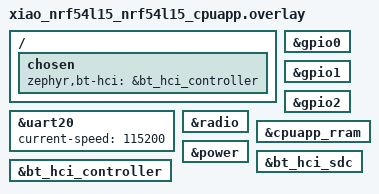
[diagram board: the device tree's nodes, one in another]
// XIAO nRF54L15 BLE Button Sample Device Tree Overlay
// Uses existing led0 and sw0 aliases from board definition

/ {
	// Use existing aliases - no need to redefine
};

// Enable GPIO controllers
&gpio0 {
	status = "okay";
};

&gpio1 {
	status = "okay";
};

&gpio2 {
	status = "okay";
};

// Configure UART for console output
&uart20 {
	status = "okay";
	current-speed = <115200>;
};

// Enable radio for Bluetooth
&radio {
	status = "okay";
};

// Configure power management
&cpuapp_rram {
	status = "okay";
};

&power {
	status = "okay";
};

&bt_hci_controller {
	status = "okay";
};

&bt_hci_sdc {
	status = "okay";
};

/ {
	chosen {
		zephyr,bt-hci = &bt_hci_controller;
	};
};
